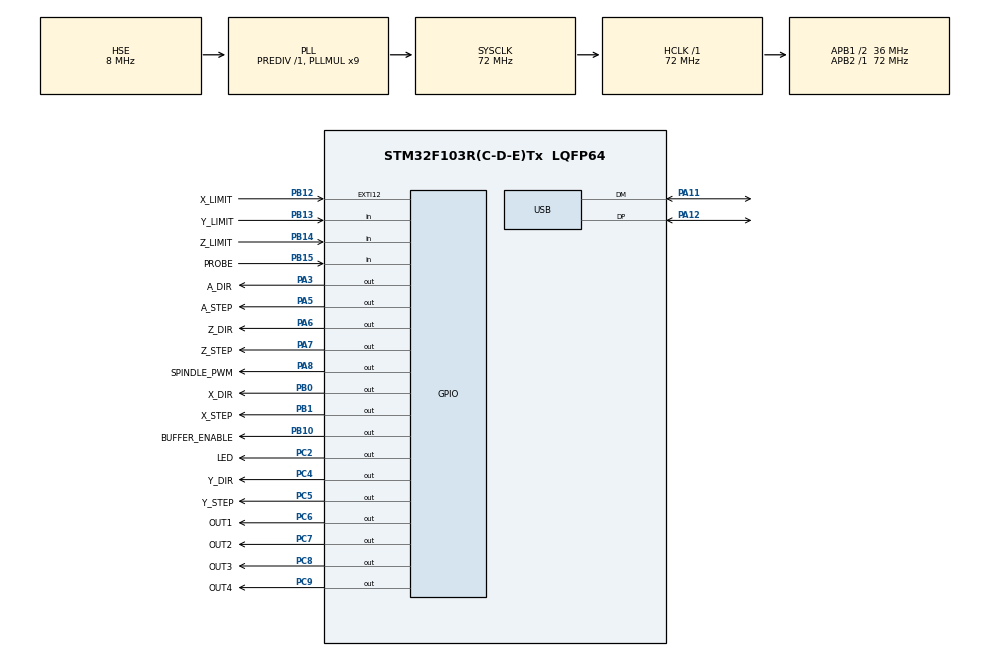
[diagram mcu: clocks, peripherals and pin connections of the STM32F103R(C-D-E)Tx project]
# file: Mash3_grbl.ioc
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Mcu.Family=STM32F1
Mcu.Name=STM32F103R(C-D-E)Tx
Mcu.Package=LQFP64
NVIC.PriorityGroup=NVIC_PRIORITYGROUP_4
NVIC.USB_LP_CAN1_RX0_IRQn=true\:0\:0\:false\:false\:true\:false\:true\:true
PA11.Mode=Device
PA11.Signal=USB_DM
PA12.Mode=Device
PA12.Signal=USB_DP
PA13.Mode=Serial_Wire
PA13.Signal=SYS_JTMS-SWDIO
PA14.Mode=Serial_Wire
PA14.Signal=SYS_JTCK-SWCLK
PA3.GPIO_Label=A_DIR
PA3.Signal=GPIO_Output
PA5.GPIO_Label=A_STEP
PA5.Signal=GPIO_Output
PA6.GPIO_Label=Z_DIR
PA6.Signal=GPIO_Output
PA7.GPIO_Label=Z_STEP
PA7.Signal=GPIO_Output
PA8.GPIO_Label=SPINDLE_PWM
PA8.Signal=GPIO_Output
PB0.GPIO_Label=X_DIR
PB0.Signal=GPIO_Output
PB1.GPIO_Label=X_STEP
PB1.Signal=GPIO_Output
PB10.GPIO_Label=BUFFER_ENABLE
PB10.Signal=GPIO_Output
PB12.GPIO_Label=X_LIMIT
PB12.Signal=GPXTI12
PB13.GPIO_Label=Y_LIMIT
PB13.Signal=GPIO_Input
PB14.GPIO_Label=Z_LIMIT
PB14.Signal=GPIO_Input
PB15.GPIO_Label=PROBE
PB15.Signal=GPIO_Input
PC2.GPIO_Label=LED
PC2.Signal=GPIO_Output
PC4.GPIO_Label=Y_DIR
PC4.Signal=GPIO_Output
PC5.GPIO_Label=Y_STEP
PC5.Signal=GPIO_Output
PC6.GPIO_Label=OUT1
PC6.Signal=GPIO_Output
PC7.GPIO_Label=OUT2
PC7.Signal=GPIO_Output
PC8.GPIO_Label=OUT3
PC8.Signal=GPIO_Output
PC9.GPIO_Label=OUT4
PC9.Signal=GPIO_Output
PD0-OSC_IN.Mode=HSE-External-Oscillator
PD0-OSC_IN.Signal=RCC_OSC_IN
PD1-OSC_OUT.Mode=HSE-External-Oscillator
PD1-OSC_OUT.Signal=RCC_OSC_OUT
ProjectManager.HeapSize=0x200
ProjectManager.StackSize=0x400
ProjectManager.TargetToolchain=STM32CubeIDE
RCC.ADCPresc=RCC_ADCPCLK2_DIV6
RCC.AHBFreq_Value=72000000
RCC.APB1CLKDivider=RCC_HCLK_DIV2
RCC.APB1Freq_Value=36000000
RCC.APB1TimFreq_Value=72000000
RCC.APB2Freq_Value=72000000
RCC.APB2TimFreq_Value=72000000
RCC.HCLKFreq_Value=72000000
RCC.PLLMUL=RCC_PLL_MUL9
RCC.SYSCLKFreq_VALUE=72000000
RCC.SYSCLKSource=RCC_SYSCLKSOURCE_PLLCLK
RCC.USBFreq_Value=48000000
USB_DEVICE.CLASS_NAME_FS=CDC
USB_DEVICE.VirtualMode=Cdc
USB_DEVICE.VirtualModeFS=Cdc_FS
VP_USB_DEVICE_VS_USB_DEVICE_CDC_FS.Mode=CDC_FS
board=custom

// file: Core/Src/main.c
/* USER CODE BEGIN Header */
/**
  ******************************************************************************
  * @file           : main.c
  * @brief          : Main program body
  ******************************************************************************
  * @attention
  *
  * Copyright (c) 2026 STMicroelectronics.
  * All rights reserved.
  *
  * This software is licensed under terms that can be found in the LICENSE file
  * in the root directory of this software component.
  * If no LICENSE file comes with this software, it is provided AS-IS.
  *
  ******************************************************************************
  */
/* USER CODE END Header */
#include "main.h"
#include "usb_device.h"

/* USER CODE BEGIN Includes */
#include "board_test.h"
#include "grbl.h"

/* USER CODE END Includes */

void SystemClock_Config(void);
static void MX_GPIO_Init(void);

int main(void)
{

  /* MCU Configuration--------------------------------------------------------*/

  /* Reset of all peripherals, Initializes the Flash interface and the Systick. */
  HAL_Init();

  /* Configure the system clock */
  SystemClock_Config();

  /* Initialize all configured peripherals */
  MX_GPIO_Init();
  BoardTest_UsbPullupInit();
  BoardTest_UsbDisconnect();
  HAL_Delay(150);
  MX_USB_DEVICE_Init();
  BoardTest_UsbConnect();
  /* USER CODE BEGIN 2 */
  BoardTest_Init();
  Grbl_Run();

  /* USER CODE END 2 */

  /* Infinite loop */
  /* USER CODE BEGIN WHILE */
  while (1)
  {
    BoardTest_Task();

    /* USER CODE END WHILE */

  }
}

void SystemClock_Config(void)
{
  RCC_OscInitTypeDef RCC_OscInitStruct = {0};
  RCC_ClkInitTypeDef RCC_ClkInitStruct = {0};
  RCC_PeriphCLKInitTypeDef PeriphClkInit = {0};

  /** Initializes the RCC Oscillators according to the specified parameters
  * in the RCC_OscInitTypeDef structure.
  */
  RCC_OscInitStruct.OscillatorType = RCC_OSCILLATORTYPE_HSE;
  RCC_OscInitStruct.HSEState = RCC_HSE_ON;
  RCC_OscInitStruct.HSEPredivValue = RCC_HSE_PREDIV_DIV1;
  RCC_OscInitStruct.HSIState = RCC_HSI_ON;
  RCC_OscInitStruct.PLL.PLLState = RCC_PLL_ON;
  RCC_OscInitStruct.PLL.PLLSource = RCC_PLLSOURCE_HSE;
  RCC_OscInitStruct.PLL.PLLMUL = RCC_PLL_MUL9;
  if (HAL_RCC_OscConfig(&RCC_OscInitStruct) != HAL_OK)
  {
    Error_Handler();
  }

  /** Initializes the CPU, AHB and APB buses clocks
  */
  RCC_ClkInitStruct.ClockType = RCC_CLOCKTYPE_HCLK|RCC_CLOCKTYPE_SYSCLK
                              |RCC_CLOCKTYPE_PCLK1|RCC_CLOCKTYPE_PCLK2;
  RCC_ClkInitStruct.SYSCLKSource = RCC_SYSCLKSOURCE_PLLCLK;
  RCC_ClkInitStruct.AHBCLKDivider = RCC_SYSCLK_DIV1;
  RCC_ClkInitStruct.APB1CLKDivider = RCC_HCLK_DIV2;
  RCC_ClkInitStruct.APB2CLKDivider = RCC_HCLK_DIV1;

  if (HAL_RCC_ClockConfig(&RCC_ClkInitStruct, FLASH_LATENCY_2) != HAL_OK)
  {
    Error_Handler();
  }
  PeriphClkInit.PeriphClockSelection = RCC_PERIPHCLK_USB;
  PeriphClkInit.UsbClockSelection = RCC_USBCLKSOURCE_PLL_DIV1_5;
  if (HAL_RCCEx_PeriphCLKConfig(&PeriphClkInit) != HAL_OK)
  {
    Error_Handler();
  }
}

static void MX_GPIO_Init(void)
{
  GPIO_InitTypeDef GPIO_InitStruct = {0};

  /* GPIO Ports Clock Enable */
  __HAL_RCC_GPIOD_CLK_ENABLE();
  __HAL_RCC_GPIOC_CLK_ENABLE();
  __HAL_RCC_GPIOA_CLK_ENABLE();
  __HAL_RCC_GPIOB_CLK_ENABLE();

  /*Configure GPIO pin Output Level */
  HAL_GPIO_WritePin(GPIOC, LED_Pin|Y_DIR_Pin|Y_STEP_Pin|OUT1_Pin
                          |OUT2_Pin|OUT3_Pin|OUT4_Pin, GPIO_PIN_RESET);

  /*Configure GPIO pin Output Level */
  HAL_GPIO_WritePin(GPIOA, A_DIR_Pin|A_STEP_Pin|Z_DIR_Pin|Z_STEP_Pin
                          |SPINDLE_PWM_Pin, GPIO_PIN_RESET);

  /*Configure GPIO pin Output Level */
  HAL_GPIO_WritePin(GPIOB, X_DIR_Pin|X_STEP_Pin|BUFFER_ENABLE_Pin, GPIO_PIN_RESET);

  /*Configure GPIO pins : LED_Pin Y_DIR_Pin Y_STEP_Pin OUT1_Pin
                           OUT2_Pin OUT3_Pin OUT4_Pin */
  GPIO_InitStruct.Pin = LED_Pin|Y_DIR_Pin|Y_STEP_Pin|OUT1_Pin
                          |OUT2_Pin|OUT3_Pin|OUT4_Pin;
  GPIO_InitStruct.Mode = GPIO_MODE_OUTPUT_PP;
  GPIO_InitStruct.Pull = GPIO_NOPULL;
  GPIO_InitStruct.Speed = GPIO_SPEED_FREQ_LOW;
  HAL_GPIO_Init(GPIOC, &GPIO_InitStruct);

  /*Configure GPIO pins : A_DIR_Pin A_STEP_Pin Z_DIR_Pin Z_STEP_Pin
                           SPINDLE_PWM_Pin */
  GPIO_InitStruct.Pin = A_DIR_Pin|A_STEP_Pin|Z_DIR_Pin|Z_STEP_Pin
                          |SPINDLE_PWM_Pin;
  GPIO_InitStruct.Mode = GPIO_MODE_OUTPUT_PP;
  GPIO_InitStruct.Pull = GPIO_NOPULL;
  GPIO_InitStruct.Speed = GPIO_SPEED_FREQ_LOW;
  HAL_GPIO_Init(GPIOA, &GPIO_InitStruct);

  /*Configure GPIO pins : X_DIR_Pin X_STEP_Pin BUFFER_ENABLE_Pin */
  GPIO_InitStruct.Pin = X_DIR_Pin|X_STEP_Pin|BUFFER_ENABLE_Pin;
  GPIO_InitStruct.Mode = GPIO_MODE_OUTPUT_PP;
  GPIO_InitStruct.Pull = GPIO_NOPULL;
  GPIO_InitStruct.Speed = GPIO_SPEED_FREQ_LOW;
  HAL_GPIO_Init(GPIOB, &GPIO_InitStruct);

  /*Configure GPIO pin : X_LIMIT_Pin */
  GPIO_InitStruct.Pin = X_LIMIT_Pin;
  GPIO_InitStruct.Mode = GPIO_MODE_IT_RISING;
  GPIO_InitStruct.Pull = GPIO_NOPULL;
  HAL_GPIO_Init(X_LIMIT_GPIO_Port, &GPIO_InitStruct);

  /*Configure GPIO pins : Y_LIMIT_Pin Z_LIMIT_Pin PROBE_Pin */
  GPIO_InitStruct.Pin = Y_LIMIT_Pin|Z_LIMIT_Pin|PROBE_Pin;
  GPIO_InitStruct.Mode = GPIO_MODE_INPUT;
  GPIO_InitStruct.Pull = GPIO_NOPULL;
  HAL_GPIO_Init(GPIOB, &GPIO_InitStruct);

}

void Error_Handler(void)
{
  __disable_irq();
  while (1)
  {
  }
}
